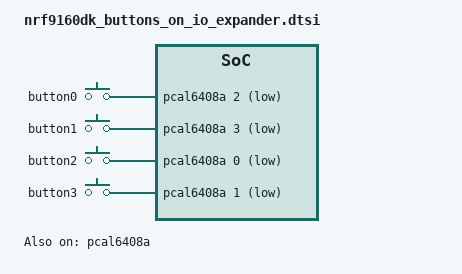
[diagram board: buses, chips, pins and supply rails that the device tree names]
/*
 * Copyright (c) 2021 Nordic Semiconductor ASA
 *
 * SPDX-License-Identifier: Apache-2.0
 */

/* NOTE: this feature is only available in nRF9160 DK v0.14.0 or later. */

&pcal6408a {
	status = "okay";
};

&button0 {
	gpios = <&pcal6408a 2 (GPIO_PULL_UP | GPIO_ACTIVE_LOW)>;
};

&button1 {
	gpios = <&pcal6408a 3 (GPIO_PULL_UP | GPIO_ACTIVE_LOW)>;
};

&button2 {
	gpios = <&pcal6408a 0 (GPIO_PULL_UP | GPIO_ACTIVE_LOW)>;
};

&button3 {
	gpios = <&pcal6408a 1 (GPIO_PULL_UP | GPIO_ACTIVE_LOW)>;
};
